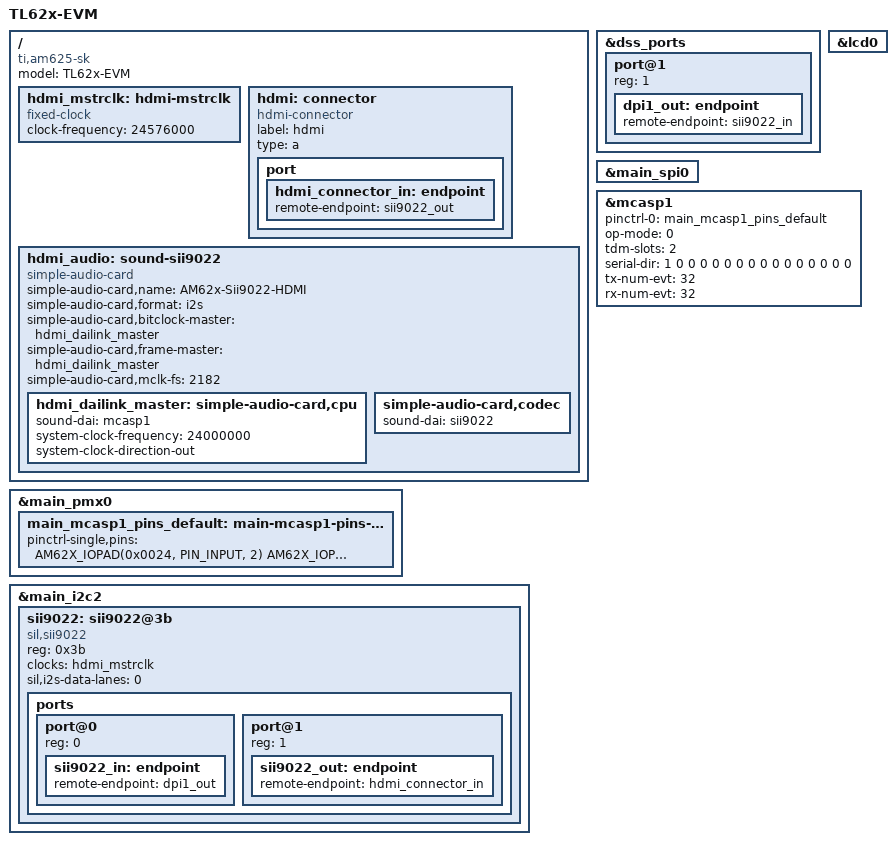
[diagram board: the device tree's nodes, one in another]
/*
 * Copyright (C) 2015 GuangZhou Tronlong co., LTD - http://www.tronlong.com
 *
 * This program is free software; you can redistribute it and/or modify
 * it under the terms of the GNU General Public License version 2 as
 * published by the Free Software Foundation.
 */


/dts-v1/;

#include "tl623x-evm.dts"

/ {
	compatible =  "ti,am625-sk", "ti,am625";
	model = "TL62x-EVM";

	hdmi_mstrclk: hdmi-mstrclk {
		compatible = "fixed-clock";
		#clock-cells = <0>;
		clock-frequency = <24576000>;
	};

	hdmi: connector {
		compatible = "hdmi-connector";
		label = "hdmi";
		type = "a";
		port {
			hdmi_connector_in: endpoint {
				remote-endpoint = <&sii9022_out>;
			};
		};
	};

	hdmi_audio:sound-sii9022 {
		compatible = "simple-audio-card";
		simple-audio-card,name = "AM62x-Sii9022-HDMI";
		simple-audio-card,format = "i2s";
		simple-audio-card,bitclock-master = <&hdmi_dailink_master>;
		simple-audio-card,frame-master = <&hdmi_dailink_master>;
		simple-audio-card,mclk-fs = <2182>;

		hdmi_dailink_master:simple-audio-card,cpu {
				sound-dai = <&mcasp1>;
				system-clock-frequency = <24000000>;
				system-clock-direction-out;
		};

		simple-audio-card,codec {
				sound-dai = <&sii9022>;
		};
	};
};

&main_pmx0 {
	main_mcasp1_pins_default: main-mcasp1-pins-default {
		pinctrl-single,pins = <
			AM62X_IOPAD(0x0024, PIN_INPUT, 2) /* (H25) OSPI0_D6.MCASP1_ACLKX */
			AM62X_IOPAD(0x0028, PIN_INPUT, 2) /* (J22) OSPI0_D7.MCASP1_AFSX */
			AM62X_IOPAD(0x0020, PIN_OUTPUT, 2) /* (J25) OSPI0_D5.MCASP1_AXR0 */
		>;
	};
};

&main_i2c2 {
        sii9022: sii9022@3b {
                #sound-dai-cells = <0>;
                compatible = "sil,sii9022";
                reg = <0x3b>;

                clocks = <&hdmi_mstrclk>;
                clock-names = "mclk";

		sil,i2s-data-lanes = < 0 >;

                ports {
                        #address-cells = <1>;
                        #size-cells = <0>;

                        port@0 {
                                reg = <0>;

                                sii9022_in: endpoint {
                                        remote-endpoint = <&dpi1_out>;
                                };
                        };

                        port@1 {
                                reg = <1>;

                                sii9022_out: endpoint {
                                        remote-endpoint = <&hdmi_connector_in>;
                                };
                        };
                };
        };
};

&dss_ports {
        /* VP2: DPI Output */
        port@1 {
                reg = <1>;

                dpi1_out: endpoint {
                        remote-endpoint = <&sii9022_in>;
                };
        };
};

&lcd0 {
	/delete-node/ port;
};

&main_spi0 {
	/delete-node/ ads7846@0;
};

&mcasp1 {
	status = "okay";
	#sound-dai-cells = <0>;

	pinctrl-names = "default";
	pinctrl-0 = <&main_mcasp1_pins_default>;

	op-mode = <0>;          /* MCASP_IIS_MODE */
	tdm-slots = <2>;

	serial-dir = <  /* 0: INACTIVE, 1: TX, 2: RX */
	       1 0 0 0
	       0 0 0 0
	       0 0 0 0
	       0 0 0 0
	>;
	tx-num-evt = <32>;
	rx-num-evt = <32>;
};
